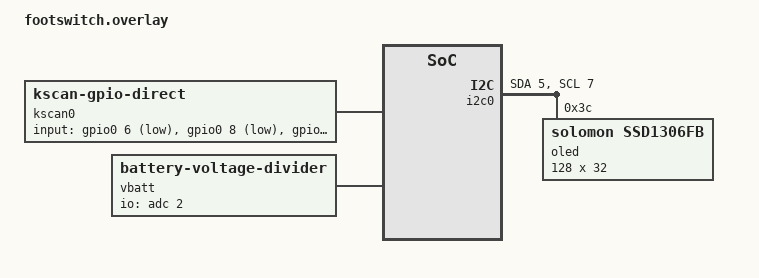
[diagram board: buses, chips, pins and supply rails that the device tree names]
/ {
    chosen {
        zmk,kscan = &kscan0;
        zmk,display = &oled;
        zephyr,display = &oled;
    };

    kscan0: kscan {
        compatible = "zmk,kscan-gpio-direct";
        
        input-gpios =
            <&gpio0 6 (GPIO_ACTIVE_LOW | GPIO_PULL_UP)>,  // 풋스위치 1 (P0.6)
            <&gpio0 8 (GPIO_ACTIVE_LOW | GPIO_PULL_UP)>,  // 풋스위치 2 (P0.8)
            <&gpio0 17 (GPIO_ACTIVE_LOW | GPIO_PULL_UP)>, // 슬라이드 스위치 (P0.17)
            <&gpio0 20 (GPIO_ACTIVE_LOW | GPIO_PULL_UP)>; // 레이어 순환 스위치
    };

    // 배터리 모니터링
    vbatt: vbatt {
        compatible = "zmk,battery-voltage-divider";
        io-channels = <&adc 2>;
        output-ohms = <2000000>;
        full-ohms = <(2000000 + 806000)>;
    };
};

&i2c0 {
    compatible = "nordic,nrf-twi";
    status = "okay";
    sda-pin = <5>;  // P0.05 핀 (I2C 데이터)
    scl-pin = <7>;  // P0.07 핀 (I2C 클럭)

    oled: ssd1306@3c {
        compatible = "solomon,ssd1306fb";
        reg = <0x3c>;
        width = <128>;
        height = <32>;
        segment-offset = <0>;
        page-offset = <0>;
        display-offset = <0>;
        multiplex-ratio = <31>;
        segment-remap;
        com-invdir;
        com-sequential;
        prechargep = <0x22>;
    };
};
